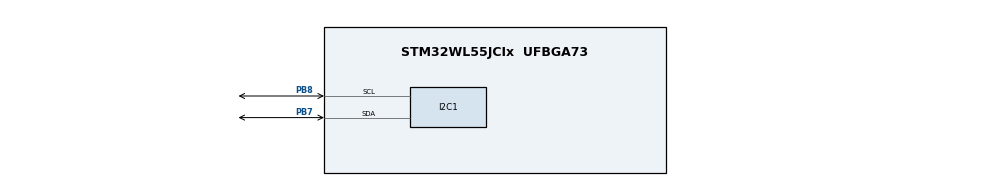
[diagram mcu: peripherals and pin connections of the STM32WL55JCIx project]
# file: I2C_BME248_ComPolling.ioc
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I2C1.Timing=0x00100D14
Mcu.Family=STM32WL
Mcu.Name=STM32WL55JCIx
Mcu.Package=UFBGA73
NVIC.PriorityGroup=NVIC_PRIORITYGROUP_4
PA2.GPIO_Label=T_VCP_RX
PA2.Signal=USART2_TX
PA3.GPIO_Label=T_VCP_RX
PA3.Signal=USART2_RX
PB7.Mode=I2C
PB7.Signal=I2C1_SDA
PB8.Mode=I2C
PB8.Signal=I2C1_SCL
PC14-OSC32_IN.GPIO_Label=RCC_OSC32_IN
PC14-OSC32_IN.Signal=RCC_OSC32_IN
PC15-OSC32_OUT.GPIO_Label=RCC_OSC32_OUT
PC15-OSC32_OUT.Signal=RCC_OSC32_OUT
ProjectManager.HeapSize=0x200
ProjectManager.StackSize=0x400
ProjectManager.TargetToolchain=STM32CubeIDE
RCC.HSE_VALUE=32000000
RCC.HSI_VALUE=16000000
RCC.LSE_VALUE=32768
RCC.VCOOutputFreq_Value=32000000
board=NUCLEO-WL55JC1

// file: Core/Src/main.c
/* USER CODE BEGIN Header */
/**
 ******************************************************************************
 * @file           : main.c
 * @brief          : Main program body
 ******************************************************************************
 * @attention
 *
 * Copyright (c) 2024 STMicroelectronics.
 * All rights reserved.
 *
 * This software is licensed under terms that can be found in the LICENSE file
 * in the root directory of this software component.
 * If no LICENSE file comes with this software, it is provided AS-IS.
 *
 ******************************************************************************
 */
/* USER CODE END Header */
#include <app_bme280.h>
#include "main.h"
#include "string.h"

void SystemClock_Config(void);
static void MX_GPIO_Init(void);
static void MX_I2C1_Init(void);

/* USER CODE BEGIN PFP */
extern void initialize_bme280_sensor(void);

/* USER CODE END PFP */
I2C_HandleTypeDef hi2c1;
/* USER CODE BEGIN 0 */
extern void initialise_monitor_handles(void);
/* USER CODE END 0 */

int main(void) {
	/* USER CODE BEGIN 1 */
	initialise_monitor_handles();
	/* USER CODE END 1 */

	/* MCU Configuration--------------------------------------------------------*/

	/* Reset of all peripherals, Initializes the Flash interface and the Systick. */
	HAL_Init();

	/* Configure the system clock */
	SystemClock_Config();

	/* Initialize all configured peripherals */
	MX_GPIO_Init();
	MX_I2C1_Init();

	/* USER CODE BEGIN 2 */
	initialize_bme280_sensor();
	/* USER CODE END 2 */

	/* Infinite loop */
	while (1) {
		sensor_data_acquisition();
	}
}

void SystemClock_Config(void) {
	RCC_OscInitTypeDef RCC_OscInitStruct = { 0 };
	RCC_ClkInitTypeDef RCC_ClkInitStruct = { 0 };

	/** Configure the main internal regulator output voltage
	 */
	__HAL_PWR_VOLTAGESCALING_CONFIG(PWR_REGULATOR_VOLTAGE_SCALE2);

	/** Initializes the CPU, AHB and APB buses clocks
	 */
	RCC_OscInitStruct.OscillatorType = RCC_OSCILLATORTYPE_MSI;
	RCC_OscInitStruct.MSIState = RCC_MSI_ON;
	RCC_OscInitStruct.MSICalibrationValue = RCC_MSICALIBRATION_DEFAULT;
	RCC_OscInitStruct.MSIClockRange = RCC_MSIRANGE_6;
	RCC_OscInitStruct.PLL.PLLState = RCC_PLL_NONE;
	if (HAL_RCC_OscConfig(&RCC_OscInitStruct) != HAL_OK) {
		Error_Handler();
	}

	/** Configure the SYSCLKSource, HCLK, PCLK1 and PCLK2 clocks dividers
	 */
	RCC_ClkInitStruct.ClockType = RCC_CLOCKTYPE_HCLK3 | RCC_CLOCKTYPE_HCLK
			| RCC_CLOCKTYPE_SYSCLK | RCC_CLOCKTYPE_PCLK1 | RCC_CLOCKTYPE_PCLK2;
	RCC_ClkInitStruct.SYSCLKSource = RCC_SYSCLKSOURCE_MSI;
	RCC_ClkInitStruct.AHBCLKDivider = RCC_SYSCLK_DIV1;
	RCC_ClkInitStruct.APB1CLKDivider = RCC_HCLK_DIV1;
	RCC_ClkInitStruct.APB2CLKDivider = RCC_HCLK_DIV1;
	RCC_ClkInitStruct.AHBCLK3Divider = RCC_SYSCLK_DIV1;

	if (HAL_RCC_ClockConfig(&RCC_ClkInitStruct, FLASH_LATENCY_0) != HAL_OK) {
		Error_Handler();
	}
}

static void MX_I2C1_Init(void) {

	hi2c1.Instance = I2C1;
	hi2c1.Init.Timing = 0x00100D14;
	hi2c1.Init.OwnAddress1 = 0;
	hi2c1.Init.AddressingMode = I2C_ADDRESSINGMODE_7BIT;
	hi2c1.Init.DualAddressMode = I2C_DUALADDRESS_DISABLE;
	hi2c1.Init.OwnAddress2 = 0;
	hi2c1.Init.OwnAddress2Masks = I2C_OA2_NOMASK;
	hi2c1.Init.GeneralCallMode = I2C_GENERALCALL_DISABLE;
	hi2c1.Init.NoStretchMode = I2C_NOSTRETCH_DISABLE;
	if (HAL_I2C_Init(&hi2c1) != HAL_OK) {
		Error_Handler();
	}

	/** Configure Analogue filter
	 */
	if (HAL_I2CEx_ConfigAnalogFilter(&hi2c1, I2C_ANALOGFILTER_ENABLE)
			!= HAL_OK) {
		Error_Handler();
	}

	/** Configure Digital filter
	 */
	if (HAL_I2CEx_ConfigDigitalFilter(&hi2c1, 0) != HAL_OK) {
		Error_Handler();
	}
	/* USER CODE BEGIN I2C1_Init 2 */
	LOGGER_LOG("\r\n");
	LOGGER_LOG("I2C initialized.\n");
	/* USER CODE END I2C1_Init 2 */
}

static void MX_GPIO_Init(void) {
	GPIO_InitTypeDef GPIO_InitStruct = { 0 };

	/* GPIO Ports Clock Enable */
	__HAL_RCC_GPIOC_CLK_ENABLE();
	__HAL_RCC_GPIOB_CLK_ENABLE();
	__HAL_RCC_GPIOA_CLK_ENABLE();

	/*Configure GPIO pins : T_VCP_RX_Pin T_VCP_RXA2_Pin */
	GPIO_InitStruct.Pin = T_VCP_RX_Pin | T_VCP_RXA2_Pin;
	GPIO_InitStruct.Mode = GPIO_MODE_AF_PP;
	GPIO_InitStruct.Pull = GPIO_NOPULL;
	GPIO_InitStruct.Speed = GPIO_SPEED_FREQ_LOW;
	GPIO_InitStruct.Alternate = GPIO_AF7_USART2;
	HAL_GPIO_Init(GPIOA, &GPIO_InitStruct);

}

void Error_Handler(void) {
	__disable_irq();
	while (1) {
	}
}
